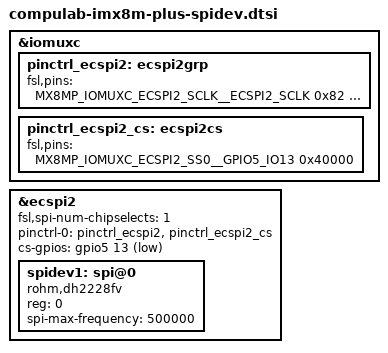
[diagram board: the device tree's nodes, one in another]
&iomuxc {

	pinctrl_ecspi2: ecspi2grp {
		fsl,pins = <
			MX8MP_IOMUXC_ECSPI2_SCLK__ECSPI2_SCLK		0x82
			MX8MP_IOMUXC_ECSPI2_MOSI__ECSPI2_MOSI		0x82
			MX8MP_IOMUXC_ECSPI2_MISO__ECSPI2_MISO		0x82
		>;
	};

	pinctrl_ecspi2_cs: ecspi2cs {
		fsl,pins = <
			MX8MP_IOMUXC_ECSPI2_SS0__GPIO5_IO13		0x40000
		>;
	};

};

&ecspi2 {
	#address-cells = <1>;
	#size-cells = <0>;
	fsl,spi-num-chipselects = <1>;
	pinctrl-names = "default";
	pinctrl-0 = <&pinctrl_ecspi2 &pinctrl_ecspi2_cs>;
	cs-gpios = <&gpio5 13 GPIO_ACTIVE_LOW>;
	status = "okay";

	spidev1: spi@0 {
		reg = <0>;
		compatible = "rohm,dh2228fv";
		spi-max-frequency = <500000>;
	};
};
